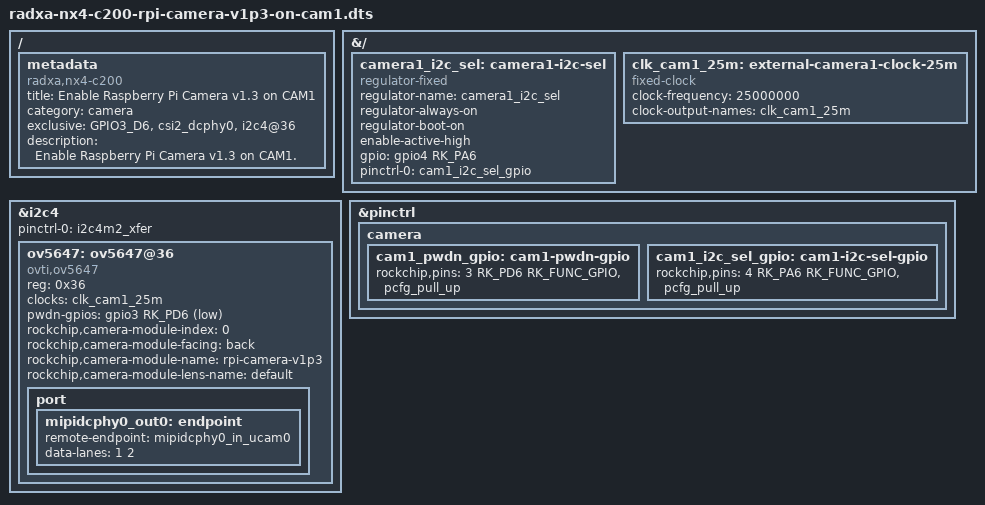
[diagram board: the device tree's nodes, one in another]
/dts-v1/;
/plugin/;

#include <dt-bindings/gpio/gpio.h>
#include <dt-bindings/pinctrl/rockchip.h>
#include <rk3576-csi2_dcphy0.dtsi>

/ {
	metadata {
		title ="Enable Raspberry Pi Camera v1.3 on CAM1";
		compatible = "radxa,nx4-c200";
		category = "camera";
		exclusive = "GPIO3_D6", "csi2_dcphy0", "i2c4@36";
		description = "Enable Raspberry Pi Camera v1.3 on CAM1.";
	};
};

&{/} {
	camera1_i2c_sel: camera1-i2c-sel {
		compatible = "regulator-fixed";
		regulator-name = "camera1_i2c_sel";
		regulator-always-on;
		regulator-boot-on;
		enable-active-high;
		gpio = <&gpio4 RK_PA6 GPIO_ACTIVE_HIGH>;
		pinctrl-names = "default";
		pinctrl-0 = <&cam1_i2c_sel_gpio>;
	};

	clk_cam1_25m: external-camera1-clock-25m {
		status = "okay";
		compatible = "fixed-clock";
		clock-frequency = <25000000>;
		clock-output-names = "clk_cam1_25m";
		#clock-cells = <0>;
	};
};

&i2c4 {
	status = "okay";
	pinctrl-0 = <&i2c4m2_xfer>;
	#address-cells = <1>;
	#size-cells = <0>;

	ov5647: ov5647@36 {
		status = "okay";
		compatible = "ovti,ov5647";
		reg = <0x36>;
		clocks = <&clk_cam1_25m>;
		pwdn-gpios = <&gpio3 RK_PD6 GPIO_ACTIVE_LOW>;
		clock-names = "ext_cam_clk";
		rockchip,camera-module-index = <0>;
		rockchip,camera-module-facing = "back";
		rockchip,camera-module-name = "rpi-camera-v1p3";
		rockchip,camera-module-lens-name = "default";

		port {
			mipidcphy0_out0: endpoint {
				remote-endpoint = <&mipidcphy0_in_ucam0>;
				data-lanes = <1 2>;
			};
		};
	};
};

&pinctrl {
	camera {
		cam1_pwdn_gpio: cam1-pwdn-gpio {
			rockchip,pins = <3 RK_PD6 RK_FUNC_GPIO &pcfg_pull_up>;
		};

		cam1_i2c_sel_gpio: cam1-i2c-sel-gpio {
			rockchip,pins = <4 RK_PA6 RK_FUNC_GPIO &pcfg_pull_up>;
		};
	};
};
